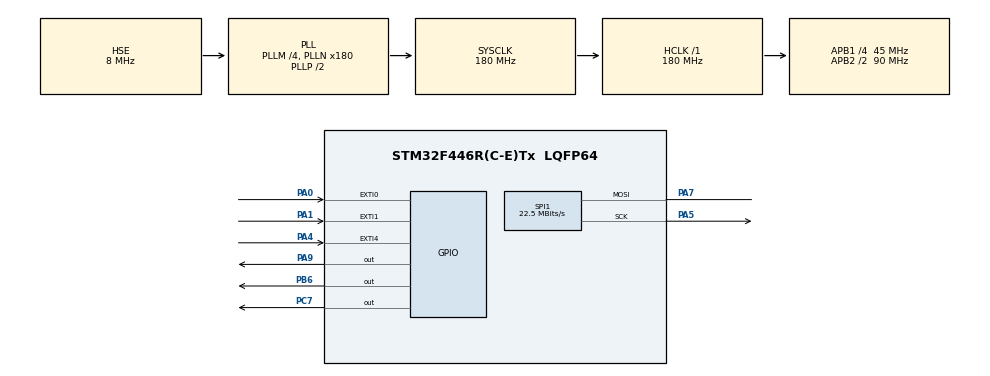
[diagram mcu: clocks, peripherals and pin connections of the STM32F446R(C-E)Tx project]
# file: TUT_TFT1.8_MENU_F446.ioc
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Mcu.Family=STM32F4
Mcu.Name=STM32F446R(C-E)Tx
Mcu.Package=LQFP64
NVIC.EXTI0_IRQn=true\:0\:0\:false\:false\:true\:true\:true
NVIC.EXTI1_IRQn=true\:0\:0\:false\:false\:true\:true\:true
NVIC.EXTI4_IRQn=true\:0\:0\:false\:false\:true\:true\:true
NVIC.PriorityGroup=NVIC_PRIORITYGROUP_4
PA0-WKUP.GPIO_ModeDefaultEXTI=GPIO_MODE_IT_FALLING
PA0-WKUP.GPIO_PuPd=GPIO_PULLDOWN
PA0-WKUP.Signal=GPXTI0
PA1.GPIO_ModeDefaultEXTI=GPIO_MODE_IT_FALLING
PA1.GPIO_PuPd=GPIO_PULLDOWN
PA1.Signal=GPXTI1
PA4.GPIO_ModeDefaultEXTI=GPIO_MODE_IT_FALLING
PA4.GPIO_PuPd=GPIO_PULLDOWN
PA4.Signal=GPXTI4
PA5.Mode=Simplex_Bidirectional_Master
PA5.Signal=SPI1_SCK
PA7.Mode=Simplex_Bidirectional_Master
PA7.Signal=SPI1_MOSI
PA9.Signal=GPIO_Output
PB6.Signal=GPIO_Output
PC7.Signal=GPIO_Output
PH0-OSC_IN.Mode=HSE-External-Oscillator
PH0-OSC_IN.Signal=RCC_OSC_IN
PH1-OSC_OUT.Mode=HSE-External-Oscillator
PH1-OSC_OUT.Signal=RCC_OSC_OUT
ProjectManager.HeapSize=0x200
ProjectManager.StackSize=0x400
ProjectManager.TargetToolchain=STM32CubeIDE
RCC.AHBFreq_Value=180000000
RCC.APB1CLKDivider=RCC_HCLK_DIV4
RCC.APB1Freq_Value=45000000
RCC.APB1TimFreq_Value=90000000
RCC.APB2CLKDivider=RCC_HCLK_DIV2
RCC.APB2Freq_Value=90000000
RCC.APB2TimFreq_Value=180000000
RCC.CortexFreq_Value=180000000
RCC.HCLKFreq_Value=180000000
RCC.HSE_VALUE=8000000
RCC.PLLM=4
RCC.PLLN=180
RCC.PLLSourceVirtual=RCC_PLLSOURCE_HSE
RCC.SYSCLKFreq_VALUE=180000000
RCC.SYSCLKSource=RCC_SYSCLKSOURCE_PLLCLK
RCC.USBFreq_Value=180000000
RCC.VCOOutputFreq_Value=360000000
SPI1.BaudRatePrescaler=SPI_BAUDRATEPRESCALER_4
SPI1.CalculateBaudRate=22.5 MBits/s
SPI1.Direction=SPI_DIRECTION_1LINE
SPI1.Mode=SPI_MODE_MASTER
SPI1.VirtualType=VM_MASTER
board=custom

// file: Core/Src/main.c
/* USER CODE BEGIN Header */
/**
  ******************************************************************************
  * @file           : main.c
  * @brief          : Main program body
  ******************************************************************************
  * @attention
  *
  * <h2><center>&copy; Copyright (c) 2020 STMicroelectronics.
  * All rights reserved.</center></h2>
  *
  * This software component is licensed by ST under BSD 3-Clause license,
  * the "License"; You may not use this file except in compliance with the
  * License. You may obtain a copy of the License at:
  *                        opensource.org/licenses/BSD-3-Clause
  *
  ******************************************************************************
  */
/* USER CODE END Header */
#include "main.h"

/* USER CODE BEGIN Includes */
#include "TFT_MENU.h"
#include "ST7735.h"
/* USER CODE END Includes */

SPI_HandleTypeDef hspi1;

void SystemClock_Config(void);
static void MX_GPIO_Init(void);
static void MX_SPI1_Init(void);

int main(void)
{

  /* MCU Configuration--------------------------------------------------------*/

  /* Reset of all peripherals, Initializes the Flash interface and the Systick. */
  HAL_Init();

  /* Configure the system clock */
  SystemClock_Config();

  /* Initialize all configured peripherals */
  MX_GPIO_Init();
  MX_SPI1_Init();
  /* USER CODE BEGIN 2 */

  ST7735_Init(0);
//  fillScreen(BLACK);
  HomeMenu();

  /* USER CODE END 2 */

  /* Infinite loop */
  while (1)
  {

    /* USER CODE BEGIN 3 */

	  Menu_Handler();
  }
  /* USER CODE END 3 */
}

void SystemClock_Config(void)
{
  RCC_OscInitTypeDef RCC_OscInitStruct = {0};
  RCC_ClkInitTypeDef RCC_ClkInitStruct = {0};

  /** Configure the main internal regulator output voltage
  */
  __HAL_RCC_PWR_CLK_ENABLE();
  __HAL_PWR_VOLTAGESCALING_CONFIG(PWR_REGULATOR_VOLTAGE_SCALE1);
  /** Initializes the RCC Oscillators according to the specified parameters
  * in the RCC_OscInitTypeDef structure.
  */
  RCC_OscInitStruct.OscillatorType = RCC_OSCILLATORTYPE_HSE;
  RCC_OscInitStruct.HSEState = RCC_HSE_ON;
  RCC_OscInitStruct.PLL.PLLState = RCC_PLL_ON;
  RCC_OscInitStruct.PLL.PLLSource = RCC_PLLSOURCE_HSE;
  RCC_OscInitStruct.PLL.PLLM = 4;
  RCC_OscInitStruct.PLL.PLLN = 180;
  RCC_OscInitStruct.PLL.PLLP = RCC_PLLP_DIV2;
  RCC_OscInitStruct.PLL.PLLQ = 2;
  RCC_OscInitStruct.PLL.PLLR = 2;
  if (HAL_RCC_OscConfig(&RCC_OscInitStruct) != HAL_OK)
  {
    Error_Handler();
  }
  /** Activate the Over-Drive mode
  */
  if (HAL_PWREx_EnableOverDrive() != HAL_OK)
  {
    Error_Handler();
  }
  /** Initializes the CPU, AHB and APB buses clocks
  */
  RCC_ClkInitStruct.ClockType = RCC_CLOCKTYPE_HCLK|RCC_CLOCKTYPE_SYSCLK
                              |RCC_CLOCKTYPE_PCLK1|RCC_CLOCKTYPE_PCLK2;
  RCC_ClkInitStruct.SYSCLKSource = RCC_SYSCLKSOURCE_PLLCLK;
  RCC_ClkInitStruct.AHBCLKDivider = RCC_SYSCLK_DIV1;
  RCC_ClkInitStruct.APB1CLKDivider = RCC_HCLK_DIV4;
  RCC_ClkInitStruct.APB2CLKDivider = RCC_HCLK_DIV2;

  if (HAL_RCC_ClockConfig(&RCC_ClkInitStruct, FLASH_LATENCY_5) != HAL_OK)
  {
    Error_Handler();
  }
}

static void MX_SPI1_Init(void)
{

  /* SPI1 parameter configuration*/
  hspi1.Instance = SPI1;
  hspi1.Init.Mode = SPI_MODE_MASTER;
  hspi1.Init.Direction = SPI_DIRECTION_1LINE;
  hspi1.Init.DataSize = SPI_DATASIZE_8BIT;
  hspi1.Init.CLKPolarity = SPI_POLARITY_LOW;
  hspi1.Init.CLKPhase = SPI_PHASE_1EDGE;
  hspi1.Init.NSS = SPI_NSS_SOFT;
  hspi1.Init.BaudRatePrescaler = SPI_BAUDRATEPRESCALER_4;
  hspi1.Init.FirstBit = SPI_FIRSTBIT_MSB;
  hspi1.Init.TIMode = SPI_TIMODE_DISABLE;
  hspi1.Init.CRCCalculation = SPI_CRCCALCULATION_DISABLE;
  hspi1.Init.CRCPolynomial = 10;
  if (HAL_SPI_Init(&hspi1) != HAL_OK)
  {
    Error_Handler();
  }

}

static void MX_GPIO_Init(void)
{
  GPIO_InitTypeDef GPIO_InitStruct = {0};

  /* GPIO Ports Clock Enable */
  __HAL_RCC_GPIOH_CLK_ENABLE();
  __HAL_RCC_GPIOA_CLK_ENABLE();
  __HAL_RCC_GPIOC_CLK_ENABLE();
  __HAL_RCC_GPIOB_CLK_ENABLE();

  /*Configure GPIO pin Output Level */
  HAL_GPIO_WritePin(GPIOC, GPIO_PIN_7, GPIO_PIN_RESET);

  /*Configure GPIO pin Output Level */
  HAL_GPIO_WritePin(GPIOA, GPIO_PIN_9, GPIO_PIN_RESET);

  /*Configure GPIO pin Output Level */
  HAL_GPIO_WritePin(GPIOB, GPIO_PIN_6, GPIO_PIN_RESET);

  /*Configure GPIO pins : PA0 PA1 PA4 */
  GPIO_InitStruct.Pin = GPIO_PIN_0|GPIO_PIN_1|GPIO_PIN_4;
  GPIO_InitStruct.Mode = GPIO_MODE_IT_FALLING;
  GPIO_InitStruct.Pull = GPIO_PULLDOWN;
  HAL_GPIO_Init(GPIOA, &GPIO_InitStruct);

  /*Configure GPIO pin : PC7 */
  GPIO_InitStruct.Pin = GPIO_PIN_7;
  GPIO_InitStruct.Mode = GPIO_MODE_OUTPUT_PP;
  GPIO_InitStruct.Pull = GPIO_NOPULL;
  GPIO_InitStruct.Speed = GPIO_SPEED_FREQ_LOW;
  HAL_GPIO_Init(GPIOC, &GPIO_InitStruct);

  /*Configure GPIO pin : PA9 */
  GPIO_InitStruct.Pin = GPIO_PIN_9;
  GPIO_InitStruct.Mode = GPIO_MODE_OUTPUT_PP;
  GPIO_InitStruct.Pull = GPIO_NOPULL;
  GPIO_InitStruct.Speed = GPIO_SPEED_FREQ_LOW;
  HAL_GPIO_Init(GPIOA, &GPIO_InitStruct);

  /*Configure GPIO pin : PB6 */
  GPIO_InitStruct.Pin = GPIO_PIN_6;
  GPIO_InitStruct.Mode = GPIO_MODE_OUTPUT_PP;
  GPIO_InitStruct.Pull = GPIO_NOPULL;
  GPIO_InitStruct.Speed = GPIO_SPEED_FREQ_LOW;
  HAL_GPIO_Init(GPIOB, &GPIO_InitStruct);

  /* EXTI interrupt init*/
  HAL_NVIC_SetPriority(EXTI0_IRQn, 0, 0);
  HAL_NVIC_EnableIRQ(EXTI0_IRQn);

  HAL_NVIC_SetPriority(EXTI1_IRQn, 0, 0);
  HAL_NVIC_EnableIRQ(EXTI1_IRQn);

  HAL_NVIC_SetPriority(EXTI4_IRQn, 0, 0);
  HAL_NVIC_EnableIRQ(EXTI4_IRQn);

}

void Error_Handler(void)
{
}

/************************ (C) COPYRIGHT STMicroelectronics *****END OF FILE****/
